# DA14683 register map
Vendor: Dialog; Series: DA14683; File version: 1.2
CPU: CM0 r1p0, little endian, MPU, FPU, 3 interrupt priority bits
Registers are 16-bit, read-write, reset 0x0 unless marked. A register's access mark holds for its fields unless they carry their own. Offsets are from the block's base; [hi:lo] are bit positions.

## NVIC — Cortex M0 NVIC registers
Base 0xE000E100
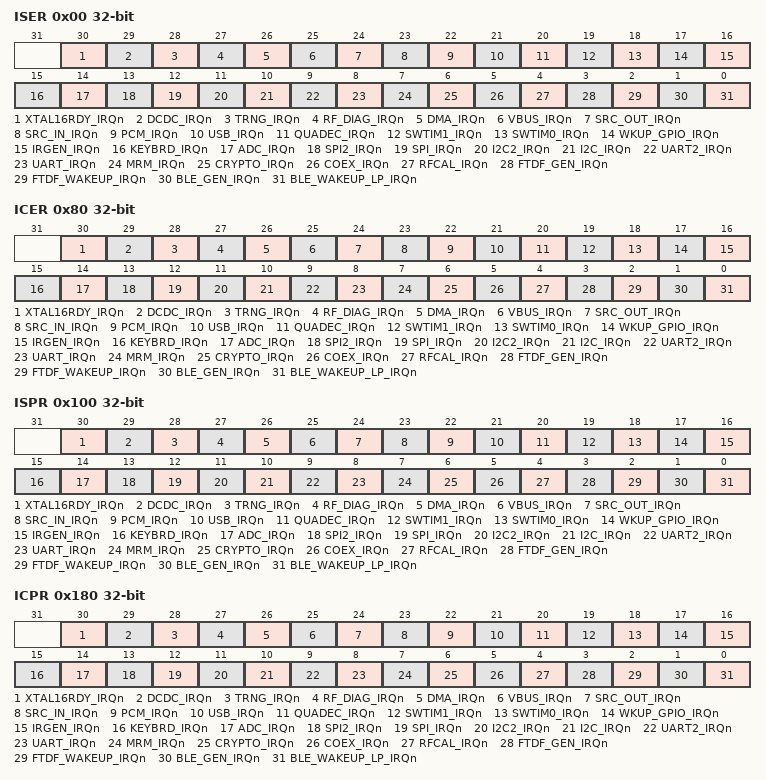
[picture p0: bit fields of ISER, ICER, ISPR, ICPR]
0x00 ISER 32-bit — Interrupt set-enable register
  [30] XTAL16RDY_IRQn — XTAL16RDY_IRQn (Interrupt set-enable bit)
  [29] DCDC_IRQn — DCDC_IRQn (Interrupt set-enable bit)
  [28] TRNG_IRQn — TRNG_IRQn (Interrupt set-enable bit)
  [27] RF_DIAG_IRQn — RF_DIAG_IRQn (Interrupt set-enable bit)
  [26] DMA_IRQn — DMA_IRQn (Interrupt set-enable bit)
  [25] VBUS_IRQn — VBUS_IRQn (Interrupt set-enable bit)
  [24] SRC_OUT_IRQn — SRC_OUT_IRQn (Interrupt set-enable bit)
  [23] SRC_IN_IRQn — SRC_IN_IRQn (Interrupt set-enable bit)
  [22] PCM_IRQn — PCM_IRQn (Interrupt set-enable bit)
  [21] USB_IRQn — USB_IRQn (Interrupt set-enable bit)
  [20] QUADEC_IRQn — QUADEC_IRQn (Interrupt set-enable bit)
  [19] SWTIM1_IRQn — SWTIM1_IRQn (Interrupt set-enable bit)
  [18] SWTIM0_IRQn — SWTIM0_IRQn (Interrupt set-enable bit)
  [17] WKUP_GPIO_IRQn — WKUP_GPIO_IRQn (Interrupt set-enable bit)
  [16] IRGEN_IRQn — IRGEN_IRQn (Interrupt set-enable bit)
  [15] KEYBRD_IRQn — KEYBRD_IRQn (Interrupt set-enable bit)
  [14] ADC_IRQn — ADC_IRQn (Interrupt set-enable bit)
  [13] SPI2_IRQn — SPI2_IRQn (Interrupt set-enable bit)
  [12] SPI_IRQn — SPI_IRQn (Interrupt set-enable bit)
  [11] I2C2_IRQn — I2C2_IRQn (Interrupt set-enable bit)
  [10] I2C_IRQn — I2C_IRQn (Interrupt set-enable bit)
  [9] UART2_IRQn — UART2_IRQn (Interrupt set-enable bit)
  [8] UART_IRQn — UART_IRQn (Interrupt set-enable bit)
  [7] MRM_IRQn — MRM_IRQn (Interrupt set-enable bit)
  [6] CRYPTO_IRQn — CRYPTO_IRQn (Interrupt set-enable bit)
  [5] COEX_IRQn — COEX_IRQn (Interrupt set-enable bit)
  [4] RFCAL_IRQn — RFCAL_IRQn (Interrupt set-enable bit)
  [3] FTDF_GEN_IRQn — FTDF_GEN_IRQn (Interrupt set-enable bit)
  [2] FTDF_WAKEUP_IRQn — FTDF_WAKEUP_IRQn (Interrupt set-enable bit)
  [1] BLE_GEN_IRQn — BLE_GEN_IRQn (Interrupt set-enable bit)
  [0] BLE_WAKEUP_LP_IRQn — BLE_WAKEUP_LP_IRQn (Interrupt set-enable bit)
0x80 ICER 32-bit — Interrupt clear-enable register
  [30] XTAL16RDY_IRQn — XTAL16RDY_IRQn (Interrupt clear-enable bit)
  [29] DCDC_IRQn — DCDC_IRQn (Interrupt clear-enable bit)
  [28] TRNG_IRQn — TRNG_IRQn (Interrupt clear-enable bit)
  [27] RF_DIAG_IRQn — RF_DIAG_IRQn (Interrupt clear-enable bit)
  [26] DMA_IRQn — DMA_IRQn (Interrupt clear-enable bit)
  [25] VBUS_IRQn — VBUS_IRQn (Interrupt clear-enable bit)
  [24] SRC_OUT_IRQn — SRC_OUT_IRQn (Interrupt clear-enable bit)
  [23] SRC_IN_IRQn — SRC_IN_IRQn (Interrupt clear-enable bit)
  [22] PCM_IRQn — PCM_IRQn (Interrupt clear-enable bit)
  [21] USB_IRQn — USB_IRQn (Interrupt clear-enable bit)
  [20] QUADEC_IRQn — QUADEC_IRQn (Interrupt clear-enable bit)
  [19] SWTIM1_IRQn — SWTIM1_IRQn (Interrupt clear-enable bit)
  [18] SWTIM0_IRQn — SWTIM0_IRQn (Interrupt clear-enable bit)
  [17] WKUP_GPIO_IRQn — WKUP_GPIO_IRQn (Interrupt clear-enable bit)
  [16] IRGEN_IRQn — IRGEN_IRQn (Interrupt clear-enable bit)
  [15] KEYBRD_IRQn — KEYBRD_IRQn (Interrupt clear-enable bit)
  [14] ADC_IRQn — ADC_IRQn (Interrupt clear-enable bit)
  [13] SPI2_IRQn — SPI2_IRQn (Interrupt clear-enable bit)
  [12] SPI_IRQn — SPI_IRQn (Interrupt clear-enable bit)
  [11] I2C2_IRQn — I2C2_IRQn (Interrupt clear-enable bit)
  [10] I2C_IRQn — I2C_IRQn (Interrupt clear-enable bit)
  [9] UART2_IRQn — UART2_IRQn (Interrupt clear-enable bit)
  [8] UART_IRQn — UART_IRQn (Interrupt clear-enable bit)
  [7] MRM_IRQn — MRM_IRQn (Interrupt clear-enable bit)
  [6] CRYPTO_IRQn — CRYPTO_IRQn (Interrupt clear-enable bit)
  [5] COEX_IRQn — COEX_IRQn (Interrupt clear-enable bit)
  [4] RFCAL_IRQn — RFCAL_IRQn (Interrupt clear-enable bit)
  [3] FTDF_GEN_IRQn — FTDF_GEN_IRQn (Interrupt clear-enable bit)
  [2] FTDF_WAKEUP_IRQn — FTDF_WAKEUP_IRQn (Interrupt clear-enable bit)
  [1] BLE_GEN_IRQn — BLE_GEN_IRQn (Interrupt clear-enable bit)
  [0] BLE_WAKEUP_LP_IRQn — BLE_WAKEUP_LP_IRQn (Interrupt clear-enable bit)
0x100 ISPR 32-bit — Interrupt set-pending register
  [30] XTAL16RDY_IRQn — XTAL16RDY_IRQn (Interrupt set-pending bit)
  [29] DCDC_IRQn — DCDC_IRQn (Interrupt set-pending bit)
  [28] TRNG_IRQn — TRNG_IRQn (Interrupt set-pending bit)
  [27] RF_DIAG_IRQn — RF_DIAG_IRQn (Interrupt set-pending bit)
  [26] DMA_IRQn — DMA_IRQn (Interrupt set-pending bit)
  [25] VBUS_IRQn — VBUS_IRQn (Interrupt set-pending bit)
  [24] SRC_OUT_IRQn — SRC_OUT_IRQn (Interrupt set-pending bit)
  [23] SRC_IN_IRQn — SRC_IN_IRQn (Interrupt set-pending bit)
  [22] PCM_IRQn — PCM_IRQn (Interrupt set-pending bit)
  [21] USB_IRQn — USB_IRQn (Interrupt set-pending bit)
  [20] QUADEC_IRQn — QUADEC_IRQn (Interrupt set-pending bit)
  [19] SWTIM1_IRQn — SWTIM1_IRQn (Interrupt set-pending bit)
  [18] SWTIM0_IRQn — SWTIM0_IRQn (Interrupt set-pending bit)
  [17] WKUP_GPIO_IRQn — WKUP_GPIO_IRQn (Interrupt set-pending bit)
  [16] IRGEN_IRQn — IRGEN_IRQn (Interrupt set-pending bit)
  [15] KEYBRD_IRQn — KEYBRD_IRQn (Interrupt set-pending bit)
  [14] ADC_IRQn — ADC_IRQn (Interrupt set-pending bit)
  [13] SPI2_IRQn — SPI2_IRQn (Interrupt set-pending bit)
  [12] SPI_IRQn — SPI_IRQn (Interrupt set-pending bit)
  [11] I2C2_IRQn — I2C2_IRQn (Interrupt set-pending bit)
  [10] I2C_IRQn — I2C_IRQn (Interrupt set-pending bit)
  [9] UART2_IRQn — UART2_IRQn (Interrupt set-pending bit)
  [8] UART_IRQn — UART_IRQn (Interrupt set-pending bit)
  [7] MRM_IRQn — MRM_IRQn (Interrupt set-pending bit)
  [6] CRYPTO_IRQn — CRYPTO_IRQn (Interrupt set-pending bit)
  [5] COEX_IRQn — COEX_IRQn (Interrupt set-pending bit)
  [4] RFCAL_IRQn — RFCAL_IRQn (Interrupt set-pending bit)
  [3] FTDF_GEN_IRQn — FTDF_GEN_IRQn (Interrupt set-pending bit)
  [2] FTDF_WAKEUP_IRQn — FTDF_WAKEUP_IRQn (Interrupt set-pending bit)
  [1] BLE_GEN_IRQn — BLE_GEN_IRQn (Interrupt set-pending bit)
  [0] BLE_WAKEUP_LP_IRQn — BLE_WAKEUP_LP_IRQn (Interrupt set-pending bit)
0x180 ICPR 32-bit — Interrupt clear-pending register
  [30] XTAL16RDY_IRQn — XTAL16RDY_IRQn (Interrupt clear-pending bit)
  [29] DCDC_IRQn — DCDC_IRQn (Interrupt clear-pending bit)
  [28] TRNG_IRQn — TRNG_IRQn (Interrupt clear-pending bit)
  [27] RF_DIAG_IRQn — RF_DIAG_IRQn (Interrupt clear-pending bit)
  [26] DMA_IRQn — DMA_IRQn (Interrupt clear-pending bit)
  [25] VBUS_IRQn — VBUS_IRQn (Interrupt clear-pending bit)
  [24] SRC_OUT_IRQn — SRC_OUT_IRQn (Interrupt clear-pending bit)
  [23] SRC_IN_IRQn — SRC_IN_IRQn (Interrupt clear-pending bit)
  [22] PCM_IRQn — PCM_IRQn (Interrupt clear-pending bit)
  [21] USB_IRQn — USB_IRQn (Interrupt clear-pending bit)
  [20] QUADEC_IRQn — QUADEC_IRQn (Interrupt clear-pending bit)
  [19] SWTIM1_IRQn — SWTIM1_IRQn (Interrupt clear-pending bit)
  [18] SWTIM0_IRQn — SWTIM0_IRQn (Interrupt clear-pending bit)
  [17] WKUP_GPIO_IRQn — WKUP_GPIO_IRQn (Interrupt clear-pending bit)
  [16] IRGEN_IRQn — IRGEN_IRQn (Interrupt clear-pending bit)
  [15] KEYBRD_IRQn — KEYBRD_IRQn (Interrupt clear-pending bit)
  [14] ADC_IRQn — ADC_IRQn (Interrupt clear-pending bit)
  [13] SPI2_IRQn — SPI2_IRQn (Interrupt clear-pending bit)
  [12] SPI_IRQn — SPI_IRQn (Interrupt clear-pending bit)
  [11] I2C2_IRQn — I2C2_IRQn (Interrupt clear-pending bit)
  [10] I2C_IRQn — I2C_IRQn (Interrupt clear-pending bit)
  [9] UART2_IRQn — UART2_IRQn (Interrupt clear-pending bit)
  [8] UART_IRQn — UART_IRQn (Interrupt clear-pending bit)
  [7] MRM_IRQn — MRM_IRQn (Interrupt clear-pending bit)
  [6] CRYPTO_IRQn — CRYPTO_IRQn (Interrupt clear-pending bit)
  [5] COEX_IRQn — COEX_IRQn (Interrupt clear-pending bit)
  [4] RFCAL_IRQn — RFCAL_IRQn (Interrupt clear-pending bit)
  [3] FTDF_GEN_IRQn — FTDF_GEN_IRQn (Interrupt clear-pending bit)
  [2] FTDF_WAKEUP_IRQn — FTDF_WAKEUP_IRQn (Interrupt clear-pending bit)
  [1] BLE_GEN_IRQn — BLE_GEN_IRQn (Interrupt clear-pending bit)
  [0] BLE_WAKEUP_LP_IRQn — BLE_WAKEUP_LP_IRQn (Interrupt clear-pending bit)
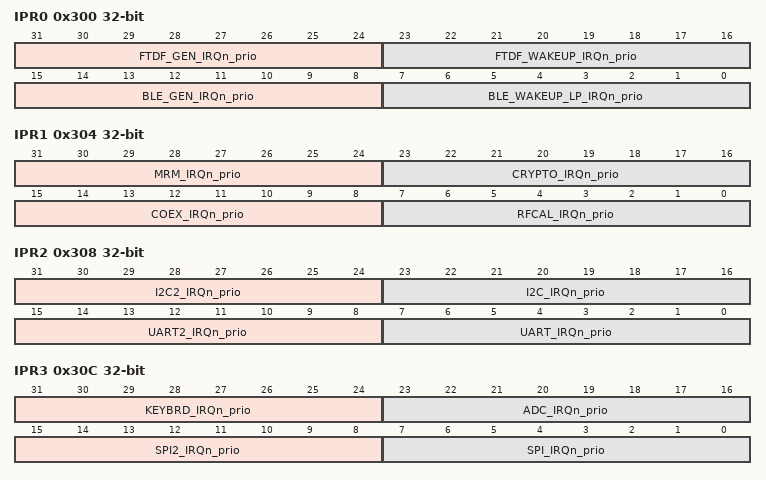
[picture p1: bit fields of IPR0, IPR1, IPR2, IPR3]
0x300 IPR0 32-bit — Interrupt priority register 0
  [31:24] FTDF_GEN_IRQn_prio — FTDF_GEN_IRQn[7:0] bits (Interrupt priority)
  [23:16] FTDF_WAKEUP_IRQn_prio — FTDF_WAKEUP_IRQn[7:0] bits (Interrupt priority)
  [15:8] BLE_GEN_IRQn_prio — BLE_GEN_IRQn[7:0] bits (Interrupt priority)
  [7:0] BLE_WAKEUP_LP_IRQn_prio — BLE_WAKEUP_LP_IRQn[7:0] bits (Interrupt priority)
0x304 IPR1 32-bit — Interrupt priority register 1
  [31:24] MRM_IRQn_prio — MRM_IRQn[7:0] bits (Interrupt priority)
  [23:16] CRYPTO_IRQn_prio — CRYPTO_IRQn[7:0] bits (Interrupt priority)
  [15:8] COEX_IRQn_prio — COEX_IRQn[7:0] bits (Interrupt priority)
  [7:0] RFCAL_IRQn_prio — RFCAL_IRQn[7:0] bits (Interrupt priority)
0x308 IPR2 32-bit — Interrupt priority register 2
  [31:24] I2C2_IRQn_prio — I2C2_IRQn[7:0] bits (Interrupt priority)
  [23:16] I2C_IRQn_prio — I2C_IRQn[7:0] bits (Interrupt priority)
  [15:8] UART2_IRQn_prio — UART2_IRQn[7:0] bits (Interrupt priority)
  [7:0] UART_IRQn_prio — UART_IRQn[7:0] bits (Interrupt priority)
0x30C IPR3 32-bit — Interrupt priority register 3
  [31:24] KEYBRD_IRQn_prio — KEYBRD_IRQn[7:0] bits (Interrupt priority)
  [23:16] ADC_IRQn_prio — ADC_IRQn[7:0] bits (Interrupt priority)
  [15:8] SPI2_IRQn_prio — SPI2_IRQn[7:0] bits (Interrupt priority)
  [7:0] SPI_IRQn_prio — SPI_IRQn[7:0] bits (Interrupt priority)
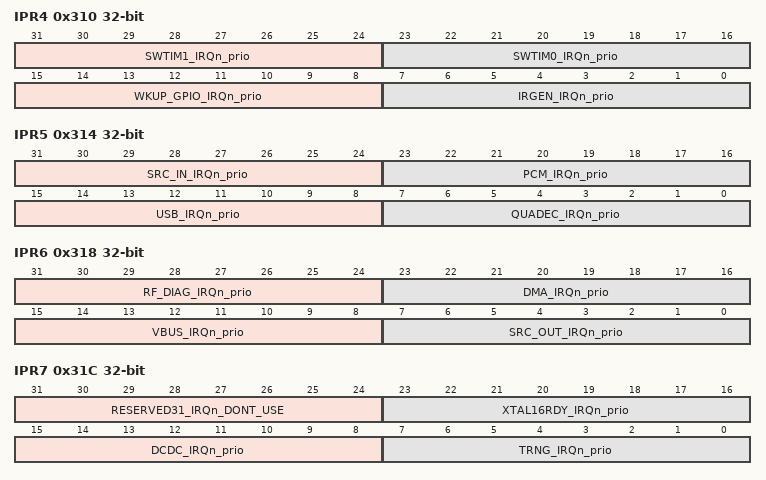
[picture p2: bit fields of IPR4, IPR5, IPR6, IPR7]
0x310 IPR4 32-bit — Interrupt priority register 4
  [31:24] SWTIM1_IRQn_prio — SWTIM1_IRQn[7:0] bits (Interrupt priority)
  [23:16] SWTIM0_IRQn_prio — SWTIM0_IRQn[7:0] bits (Interrupt priority)
  [15:8] WKUP_GPIO_IRQn_prio — WKUP_GPIO_IRQn[7:0] bits (Interrupt priority)
  [7:0] IRGEN_IRQn_prio — IRGEN_IRQn[7:0] bits (Interrupt priority)
0x314 IPR5 32-bit — Interrupt priority register 5
  [31:24] SRC_IN_IRQn_prio — SRC_IN_IRQn[7:0] bits (Interrupt priority)
  [23:16] PCM_IRQn_prio — PCM_IRQn[7:0] bits (Interrupt priority)
  [15:8] USB_IRQn_prio — USB_IRQn[7:0] bits (Interrupt priority)
  [7:0] QUADEC_IRQn_prio — QUADEC_IRQn[7:0] bits (Interrupt priority)
0x318 IPR6 32-bit — Interrupt priority register 6
  [31:24] RF_DIAG_IRQn_prio — RF_DIAG_IRQn[7:0] bits (Interrupt priority)
  [23:16] DMA_IRQn_prio — DMA_IRQn[7:0] bits (Interrupt priority)
  [15:8] VBUS_IRQn_prio — VBUS_IRQn[7:0] bits (Interrupt priority)
  [7:0] SRC_OUT_IRQn_prio — SRC_OUT_IRQn[7:0] bits (Interrupt priority)
0x31C IPR7 32-bit — Interrupt priority register 7
  [31:24] RESERVED31_IRQn_DONT_USE — RESERVED31_IRQn[7:0] bits (Reserved)
  [23:16] XTAL16RDY_IRQn_prio — XTAL16RDY_IRQn[7:0] bits (Interrupt priority)
  [15:8] DCDC_IRQn_prio — DCDC_IRQn[7:0] bits (Interrupt priority)
  [7:0] TRNG_IRQn_prio — TRNG_IRQn[7:0] bits (Interrupt priority)

## Notices in the file
Copyright (C) 2018 Dialog Semiconductor.
This computer program includes Confidential, Proprietary Information
of Dialog Semiconductor. All Rights Reserved.
